# max32630 register map
Vendor: Maxim Integrated; Series: max3263x; File version: 1.2
CPU: CM4 r0p1, little endian, no MPU, FPU, 3 interrupt priority bits
Registers are 32-bit, read-write, reset 0x0 unless marked. A register's access mark holds for its fields unless they carry their own. Offsets are from the block's base; [hi:lo] are bit positions; 'fields as' and 'values as' point back to an identical list.

## GPIO — General Purpose I/O Ports (GPIO)
Base 0x4000A000
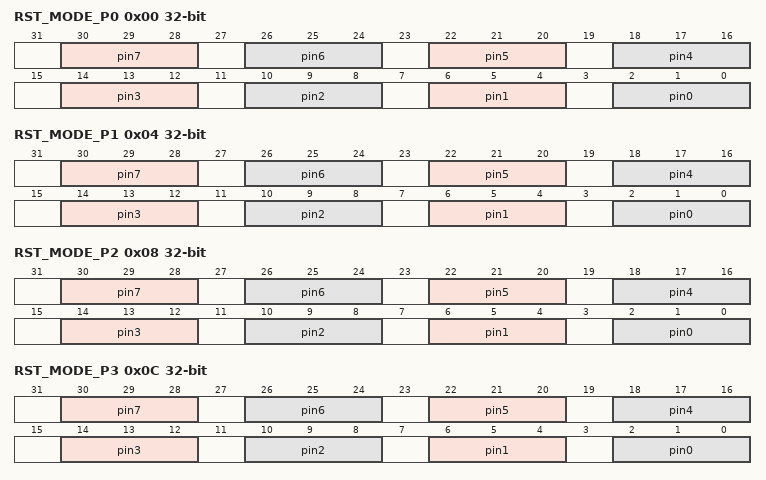
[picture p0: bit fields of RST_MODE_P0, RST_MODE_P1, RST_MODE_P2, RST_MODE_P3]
0x00 RST_MODE_P0 — Port P0 Default (Power-On Reset) Output Drive Mode
  [30:28] pin7 — P0.7 Default Output Drive Mode
  [26:24] pin6 — P0.6 Default Output Drive Mode
  [22:20] pin5 — P0.5 Default Output Drive Mode
  [18:16] pin4 — P0.4 Default Output Drive Mode
  [14:12] pin3 — P0.3 Default Output Drive Mode
  [10:8] pin2 — P0.2 Default Output Drive Mode
  [6:4] pin1 — P0.1 Default Output Drive Mode
  [2:0] pin0 — P0.0 Default Output Drive Mode
0x04 RST_MODE_P1 — Port P1 Default (Power-On Reset) Output Drive Mode
  [30:28] pin7 — P1.7 Default Output Drive Mode
  [26:24] pin6 — P1.6 Default Output Drive Mode
  [22:20] pin5 — P1.5 Default Output Drive Mode
  [18:16] pin4 — P1.4 Default Output Drive Mode
  [14:12] pin3 — P1.3 Default Output Drive Mode
  [10:8] pin2 — P1.2 Default Output Drive Mode
  [6:4] pin1 — P1.1 Default Output Drive Mode
  [2:0] pin0 — P1.0 Default Output Drive Mode
0x08 RST_MODE_P2 — Port P2 Default (Power-On Reset) Output Drive Mode
  [30:28] pin7 — P2.7 Default Output Drive Mode
  [26:24] pin6 — P2.6 Default Output Drive Mode
  [22:20] pin5 — P2.5 Default Output Drive Mode
  [18:16] pin4 — P2.4 Default Output Drive Mode
  [14:12] pin3 — P2.3 Default Output Drive Mode
  [10:8] pin2 — P2.2 Default Output Drive Mode
  [6:4] pin1 — P2.1 Default Output Drive Mode
  [2:0] pin0 — P2.0 Default Output Drive Mode
0x0C RST_MODE_P3 — Port P3 Default (Power-On Reset) Output Drive Mode
  [30:28] pin7 — P3.7 Default Output Drive Mode
  [26:24] pin6 — P3.6 Default Output Drive Mode
  [22:20] pin5 — P3.5 Default Output Drive Mode
  [18:16] pin4 — P3.4 Default Output Drive Mode
  [14:12] pin3 — P3.3 Default Output Drive Mode
  [10:8] pin2 — P3.2 Default Output Drive Mode
  [6:4] pin1 — P3.1 Default Output Drive Mode
  [2:0] pin0 — P3.0 Default Output Drive Mode
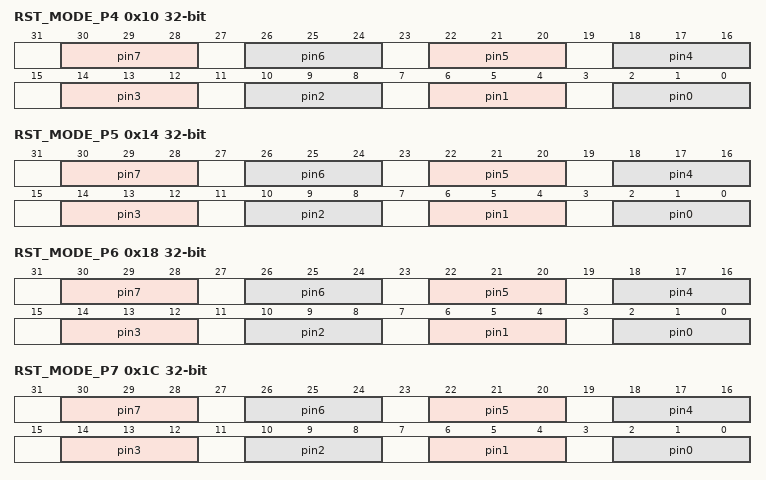
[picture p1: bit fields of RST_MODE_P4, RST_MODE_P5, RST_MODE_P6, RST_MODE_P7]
0x10 RST_MODE_P4 — Port P4 Default (Power-On Reset) Output Drive Mode
  [30:28] pin7 — P4.7 Default Output Drive Mode
  [26:24] pin6 — P4.6 Default Output Drive Mode
  [22:20] pin5 — P4.5 Default Output Drive Mode
  [18:16] pin4 — P4.4 Default Output Drive Mode
  [14:12] pin3 — P4.3 Default Output Drive Mode
  [10:8] pin2 — P4.2 Default Output Drive Mode
  [6:4] pin1 — P4.1 Default Output Drive Mode
  [2:0] pin0 — P4.0 Default Output Drive Mode
0x14 RST_MODE_P5 — Port P5 Default (Power-On Reset) Output Drive Mode
  [30:28] pin7 — P5.7 Default Output Drive Mode
  [26:24] pin6 — P5.6 Default Output Drive Mode
  [22:20] pin5 — P5.5 Default Output Drive Mode
  [18:16] pin4 — P5.4 Default Output Drive Mode
  [14:12] pin3 — P5.3 Default Output Drive Mode
  [10:8] pin2 — P5.2 Default Output Drive Mode
  [6:4] pin1 — P5.1 Default Output Drive Mode
  [2:0] pin0 — P5.0 Default Output Drive Mode
0x18 RST_MODE_P6 — Port P6 Default (Power-On Reset) Output Drive Mode
  [30:28] pin7 — P6.7 Default Output Drive Mode
  [26:24] pin6 — P6.6 Default Output Drive Mode
  [22:20] pin5 — P6.5 Default Output Drive Mode
  [18:16] pin4 — P6.4 Default Output Drive Mode
  [14:12] pin3 — P6.3 Default Output Drive Mode
  [10:8] pin2 — P6.2 Default Output Drive Mode
  [6:4] pin1 — P6.1 Default Output Drive Mode
  [2:0] pin0 — P6.0 Default Output Drive Mode
0x1C RST_MODE_P7 — Port P7 Default (Power-On Reset) Output Drive Mode
  [30:28] pin7 — P7.7 Default Output Drive Mode
  [26:24] pin6 — P7.6 Default Output Drive Mode
  [22:20] pin5 — P7.5 Default Output Drive Mode
  [18:16] pin4 — P7.4 Default Output Drive Mode
  [14:12] pin3 — P7.3 Default Output Drive Mode
  [10:8] pin2 — P7.2 Default Output Drive Mode
  [6:4] pin1 — P7.1 Default Output Drive Mode
  [2:0] pin0 — P7.0 Default Output Drive Mode
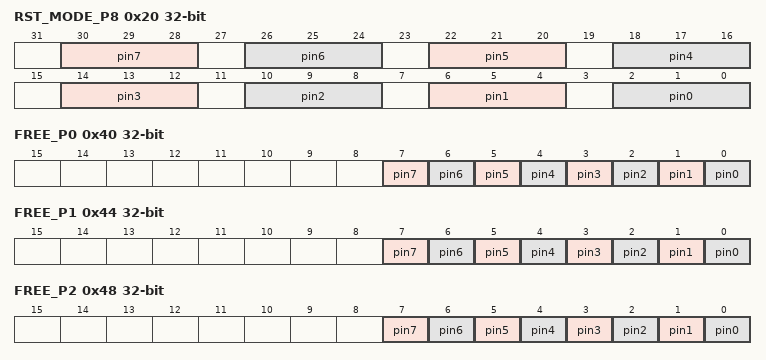
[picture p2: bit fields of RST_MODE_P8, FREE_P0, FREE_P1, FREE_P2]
0x20 RST_MODE_P8 — Port P8 Default (Power-On Reset) Output Drive Mode
  [30:28] pin7 — P8.7 Default Output Drive Mode
  [26:24] pin6 — P8.6 Default Output Drive Mode
  [22:20] pin5 — P8.5 Default Output Drive Mode
  [18:16] pin4 — P8.4 Default Output Drive Mode
  [14:12] pin3 — P8.3 Default Output Drive Mode
  [10:8] pin2 — P8.2 Default Output Drive Mode
  [6:4] pin1 — P8.1 Default Output Drive Mode
  [2:0] pin0 — P8.0 Default Output Drive Mode
0x40 FREE_P0 — Port P0 Free for GPIO Operation Flags
  [7] pin7 ro — P0.7 GPIO Mode Acknowledge
  [6] pin6 ro — P0.6 GPIO Mode Acknowledge
  [5] pin5 ro — P0.5 GPIO Mode Acknowledge
  [4] pin4 ro — P0.4 GPIO Mode Acknowledge
  [3] pin3 ro — P0.3 GPIO Mode Acknowledge
  [2] pin2 ro — P0.2 GPIO Mode Acknowledge
  [1] pin1 ro — P0.1 GPIO Mode Acknowledge
  [0] pin0 ro — P0.0 GPIO Mode Acknowledge
0x44 FREE_P1 — Port P1 Free for GPIO Operation Flags
  [7] pin7 ro — P1.7 GPIO Mode Acknowledge
  [6] pin6 ro — P1.6 GPIO Mode Acknowledge
  [5] pin5 ro — P1.5 GPIO Mode Acknowledge
  [4] pin4 ro — P1.4 GPIO Mode Acknowledge
  [3] pin3 ro — P1.3 GPIO Mode Acknowledge
  [2] pin2 ro — P1.2 GPIO Mode Acknowledge
  [1] pin1 ro — P1.1 GPIO Mode Acknowledge
  [0] pin0 ro — P1.0 GPIO Mode Acknowledge
0x48 FREE_P2 — Port P2 Free for GPIO Operation Flags
  [7] pin7 ro — P2.7 GPIO Mode Acknowledge
  [6] pin6 ro — P2.6 GPIO Mode Acknowledge
  [5] pin5 ro — P2.5 GPIO Mode Acknowledge
  [4] pin4 ro — P2.4 GPIO Mode Acknowledge
  [3] pin3 ro — P2.3 GPIO Mode Acknowledge
  [2] pin2 ro — P2.2 GPIO Mode Acknowledge
  [1] pin1 ro — P2.1 GPIO Mode Acknowledge
  [0] pin0 ro — P2.0 GPIO Mode Acknowledge
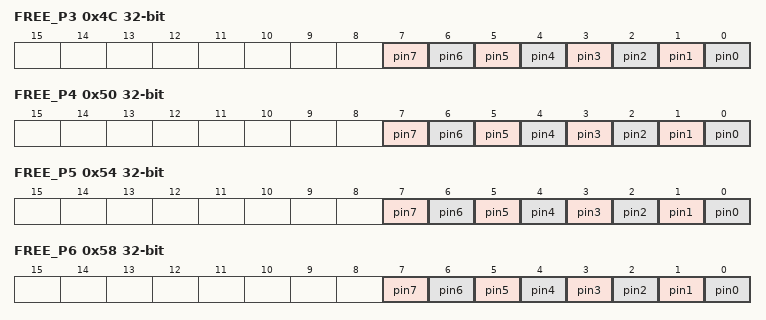
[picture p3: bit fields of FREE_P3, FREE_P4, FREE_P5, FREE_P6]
0x4C FREE_P3 — Port P3 Free for GPIO Operation Flags
  [7] pin7 ro — P3.7 GPIO Mode Acknowledge
  [6] pin6 ro — P3.6 GPIO Mode Acknowledge
  [5] pin5 ro — P3.5 GPIO Mode Acknowledge
  [4] pin4 ro — P3.4 GPIO Mode Acknowledge
  [3] pin3 ro — P3.3 GPIO Mode Acknowledge
  [2] pin2 ro — P3.2 GPIO Mode Acknowledge
  [1] pin1 ro — P3.1 GPIO Mode Acknowledge
  [0] pin0 ro — P3.0 GPIO Mode Acknowledge
0x50 FREE_P4 — Port P4 Free for GPIO Operation Flags
  [7] pin7 ro — P4.7 GPIO Mode Acknowledge
  [6] pin6 ro — P4.6 GPIO Mode Acknowledge
  [5] pin5 ro — P4.5 GPIO Mode Acknowledge
  [4] pin4 ro — P4.4 GPIO Mode Acknowledge
  [3] pin3 ro — P4.3 GPIO Mode Acknowledge
  [2] pin2 ro — P4.2 GPIO Mode Acknowledge
  [1] pin1 ro — P4.1 GPIO Mode Acknowledge
  [0] pin0 ro — P4.0 GPIO Mode Acknowledge
0x54 FREE_P5 — Port P5 Free for GPIO Operation Flags
  [7] pin7 ro — P5.7 GPIO Mode Acknowledge
  [6] pin6 ro — P5.6 GPIO Mode Acknowledge
  [5] pin5 ro — P5.5 GPIO Mode Acknowledge
  [4] pin4 ro — P5.4 GPIO Mode Acknowledge
  [3] pin3 ro — P5.3 GPIO Mode Acknowledge
  [2] pin2 ro — P5.2 GPIO Mode Acknowledge
  [1] pin1 ro — P5.1 GPIO Mode Acknowledge
  [0] pin0 ro — P5.0 GPIO Mode Acknowledge
0x58 FREE_P6 — Port P6 Free for GPIO Operation Flags
  [7] pin7 ro — P6.7 GPIO Mode Acknowledge
  [6] pin6 ro — P6.6 GPIO Mode Acknowledge
  [5] pin5 ro — P6.5 GPIO Mode Acknowledge
  [4] pin4 ro — P6.4 GPIO Mode Acknowledge
  [3] pin3 ro — P6.3 GPIO Mode Acknowledge
  [2] pin2 ro — P6.2 GPIO Mode Acknowledge
  [1] pin1 ro — P6.1 GPIO Mode Acknowledge
  [0] pin0 ro — P6.0 GPIO Mode Acknowledge
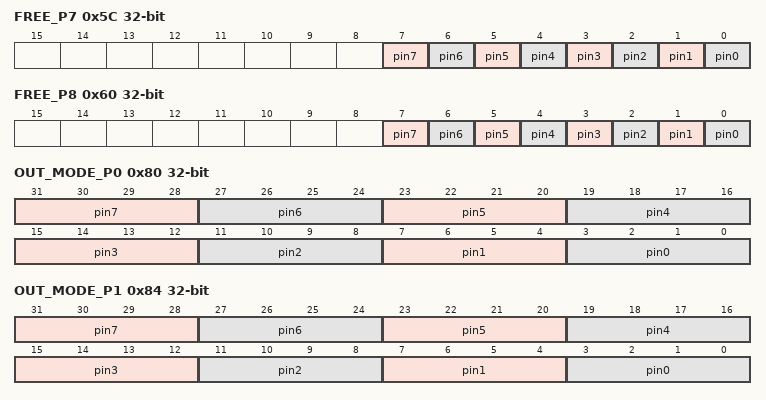
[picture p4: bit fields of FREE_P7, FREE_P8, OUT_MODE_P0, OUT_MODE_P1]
0x5C FREE_P7 — Port P7 Free for GPIO Operation Flags
  [7] pin7 ro — P7.7 GPIO Mode Acknowledge
  [6] pin6 ro — P7.6 GPIO Mode Acknowledge
  [5] pin5 ro — P7.5 GPIO Mode Acknowledge
  [4] pin4 ro — P7.4 GPIO Mode Acknowledge
  [3] pin3 ro — P7.3 GPIO Mode Acknowledge
  [2] pin2 ro — P7.2 GPIO Mode Acknowledge
  [1] pin1 ro — P7.1 GPIO Mode Acknowledge
  [0] pin0 ro — P7.0 GPIO Mode Acknowledge
0x60 FREE_P8 — Port P8 Free for GPIO Operation Flags
  [7] pin7 ro — P8.7 (Not Implemented)
  [6] pin6 ro — P8.6 (Not Implemented)
  [5] pin5 ro — P8.5 (Not Implemented)
  [4] pin4 ro — P8.4 (Not Implemented)
  [3] pin3 ro — P8.3 (Not Implemented)
  [2] pin2 ro — P8.2 (Not Implemented)
  [1] pin1 ro — P8.1 GPIO Mode Acknowledge
  [0] pin0 ro — P8.0 GPIO Mode Acknowledge
0x80 OUT_MODE_P0 — Port P0 GPIO Output Drive Mode
  [31:28] pin7 — P0.7 Output Drive Mode
  [27:24] pin6 — P0.6 Output Drive Mode
  [23:20] pin5 — P0.5 Output Drive Mode
  [19:16] pin4 — P0.4 Output Drive Mode
  [15:12] pin3 — P0.3 Output Drive Mode
  [11:8] pin2 — P0.2 Output Drive Mode
  [7:4] pin1 — P0.1 Output Drive Mode
  [3:0] pin0 — P0.0 Output Drive Mode
0x84 OUT_MODE_P1 — Port P1 GPIO Output Drive Mode
  [31:28] pin7 — P1.7 Output Drive Mode
  [27:24] pin6 — P1.6 Output Drive Mode
  [23:20] pin5 — P1.5 Output Drive Mode
  [19:16] pin4 — P1.4 Output Drive Mode
  [15:12] pin3 — P1.3 Output Drive Mode
  [11:8] pin2 — P1.2 Output Drive Mode
  [7:4] pin1 — P1.1 Output Drive Mode
  [3:0] pin0 — P1.0 Output Drive Mode
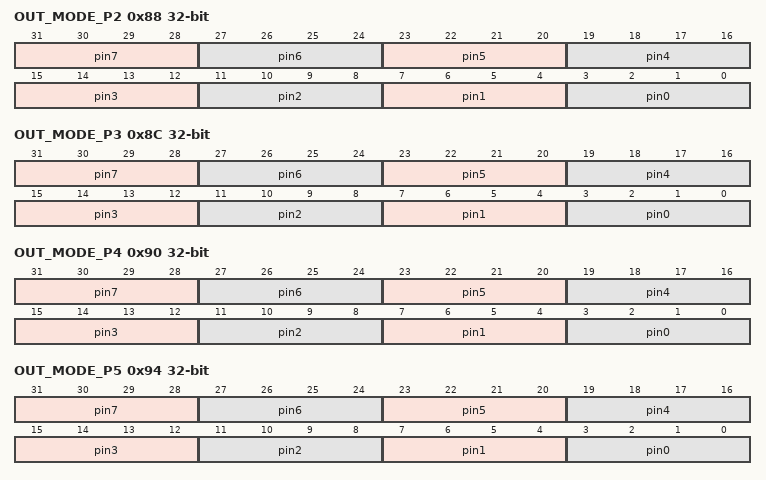
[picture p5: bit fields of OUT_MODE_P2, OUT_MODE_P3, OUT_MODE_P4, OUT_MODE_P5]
0x88 OUT_MODE_P2 — Port P2 GPIO Output Drive Mode
  [31:28] pin7 — P2.7 Output Drive Mode
  [27:24] pin6 — P2.6 Output Drive Mode
  [23:20] pin5 — P2.5 Output Drive Mode
  [19:16] pin4 — P2.4 Output Drive Mode
  [15:12] pin3 — P2.3 Output Drive Mode
  [11:8] pin2 — P2.2 Output Drive Mode
  [7:4] pin1 — P2.1 Output Drive Mode
  [3:0] pin0 — P2.0 Output Drive Mode
0x8C OUT_MODE_P3 — Port P3 GPIO Output Drive Mode
  [31:28] pin7 — P3.7 Output Drive Mode
  [27:24] pin6 — P3.6 Output Drive Mode
  [23:20] pin5 — P3.5 Output Drive Mode
  [19:16] pin4 — P3.4 Output Drive Mode
  [15:12] pin3 — P3.3 Output Drive Mode
  [11:8] pin2 — P3.2 Output Drive Mode
  [7:4] pin1 — P3.1 Output Drive Mode
  [3:0] pin0 — P3.0 Output Drive Mode
0x90 OUT_MODE_P4 — Port P4 GPIO Output Drive Mode
  [31:28] pin7 — P4.7 Output Drive Mode
  [27:24] pin6 — P4.6 Output Drive Mode
  [23:20] pin5 — P4.5 Output Drive Mode
  [19:16] pin4 — P4.4 Output Drive Mode
  [15:12] pin3 — P4.3 Output Drive Mode
  [11:8] pin2 — P4.2 Output Drive Mode
  [7:4] pin1 — P4.1 Output Drive Mode
  [3:0] pin0 — P4.0 Output Drive Mode
0x94 OUT_MODE_P5 — Port P5 GPIO Output Drive Mode
  [31:28] pin7 — P5.7 Output Drive Mode
  [27:24] pin6 — P5.6 Output Drive Mode
  [23:20] pin5 — P5.5 Output Drive Mode
  [19:16] pin4 — P5.4 Output Drive Mode
  [15:12] pin3 — P5.3 Output Drive Mode
  [11:8] pin2 — P5.2 Output Drive Mode
  [7:4] pin1 — P5.1 Output Drive Mode
  [3:0] pin0 — P5.0 Output Drive Mode
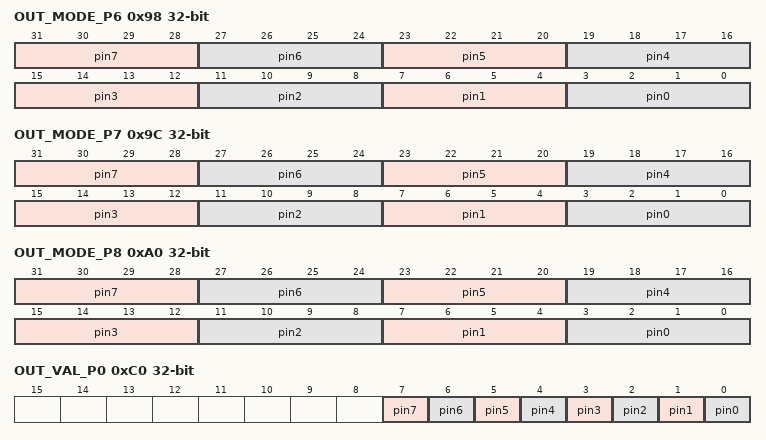
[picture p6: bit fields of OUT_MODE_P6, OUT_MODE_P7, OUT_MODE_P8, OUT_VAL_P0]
0x98 OUT_MODE_P6 — Port P6 GPIO Output Drive Mode
  [31:28] pin7 — P6.7 Output Drive Mode
  [27:24] pin6 — P6.6 Output Drive Mode
  [23:20] pin5 — P6.5 Output Drive Mode
  [19:16] pin4 — P6.4 Output Drive Mode
  [15:12] pin3 — P6.3 Output Drive Mode
  [11:8] pin2 — P6.2 Output Drive Mode
  [7:4] pin1 — P6.1 Output Drive Mode
  [3:0] pin0 — P6.0 Output Drive Mode
0x9C OUT_MODE_P7 — Port P7 GPIO Output Drive Mode
  [31:28] pin7 — P7.7 Output Drive Mode
  [27:24] pin6 — P7.6 Output Drive Mode
  [23:20] pin5 — P7.5 Output Drive Mode
  [19:16] pin4 — P7.4 Output Drive Mode
  [15:12] pin3 — P7.3 Output Drive Mode
  [11:8] pin2 — P7.2 Output Drive Mode
  [7:4] pin1 — P7.1 Output Drive Mode
  [3:0] pin0 — P7.0 Output Drive Mode
0xA0 OUT_MODE_P8 — Port P8 GPIO Output Drive Mode
  [31:28] pin7 — P8.7 (No Connect)
  [27:24] pin6 — P8.6 (No Connect)
  [23:20] pin5 — P8.5 (No Connect)
  [19:16] pin4 — P8.4 (No Connect)
  [15:12] pin3 — P8.3 (No Connect)
  [11:8] pin2 — P8.2 (No Connect)
  [7:4] pin1 — P8.1 Output Drive Mode
  [3:0] pin0 — P8.0 Output Drive Mode
0xC0 OUT_VAL_P0 — Port P0 GPIO Output Value
  [7] pin7 — P0.7 GPIO Output Drive Value
  [6] pin6 — P0.6 GPIO Output Drive Value
  [5] pin5 — P0.5 GPIO Output Drive Value
  [4] pin4 — P0.4 GPIO Output Drive Value
  [3] pin3 — P0.3 GPIO Output Drive Value
  [2] pin2 — P0.2 GPIO Output Drive Value
  [1] pin1 — P0.1 GPIO Output Drive Value
  [0] pin0 — P0.0 GPIO Output Drive Value
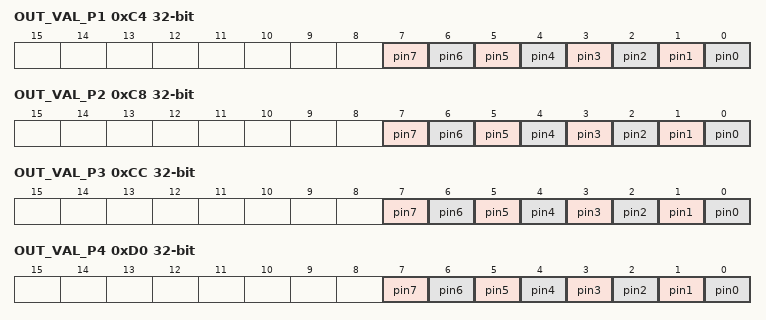
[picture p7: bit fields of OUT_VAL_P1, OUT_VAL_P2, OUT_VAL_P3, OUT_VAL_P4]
0xC4 OUT_VAL_P1 — Port P1 GPIO Output Value
  [7] pin7 — P1.7 GPIO Output Drive Value
  [6] pin6 — P1.6 GPIO Output Drive Value
  [5] pin5 — P1.5 GPIO Output Drive Value
  [4] pin4 — P1.4 GPIO Output Drive Value
  [3] pin3 — P1.3 GPIO Output Drive Value
  [2] pin2 — P1.2 GPIO Output Drive Value
  [1] pin1 — P1.1 GPIO Output Drive Value
  [0] pin0 — P1.0 GPIO Output Drive Value
0xC8 OUT_VAL_P2 — Port P2 GPIO Output Value
  [7] pin7 — P2.7 GPIO Output Drive Value
  [6] pin6 — P2.6 GPIO Output Drive Value
  [5] pin5 — P2.5 GPIO Output Drive Value
  [4] pin4 — P2.4 GPIO Output Drive Value
  [3] pin3 — P2.3 GPIO Output Drive Value
  [2] pin2 — P2.2 GPIO Output Drive Value
  [1] pin1 — P2.1 GPIO Output Drive Value
  [0] pin0 — P2.0 GPIO Output Drive Value
0xCC OUT_VAL_P3 — Port P3 GPIO Output Value
  [7] pin7 — P3.7 GPIO Output Drive Value
  [6] pin6 — P3.6 GPIO Output Drive Value
  [5] pin5 — P3.5 GPIO Output Drive Value
  [4] pin4 — P3.4 GPIO Output Drive Value
  [3] pin3 — P3.3 GPIO Output Drive Value
  [2] pin2 — P3.2 GPIO Output Drive Value
  [1] pin1 — P3.1 GPIO Output Drive Value
  [0] pin0 — P3.0 GPIO Output Drive Value
0xD0 OUT_VAL_P4 — Port P4 GPIO Output Value
  [7] pin7 — P4.7 GPIO Output Drive Value
  [6] pin6 — P4.6 GPIO Output Drive Value
  [5] pin5 — P4.5 GPIO Output Drive Value
  [4] pin4 — P4.4 GPIO Output Drive Value
  [3] pin3 — P4.3 GPIO Output Drive Value
  [2] pin2 — P4.2 GPIO Output Drive Value
  [1] pin1 — P4.1 GPIO Output Drive Value
  [0] pin0 — P4.0 GPIO Output Drive Value
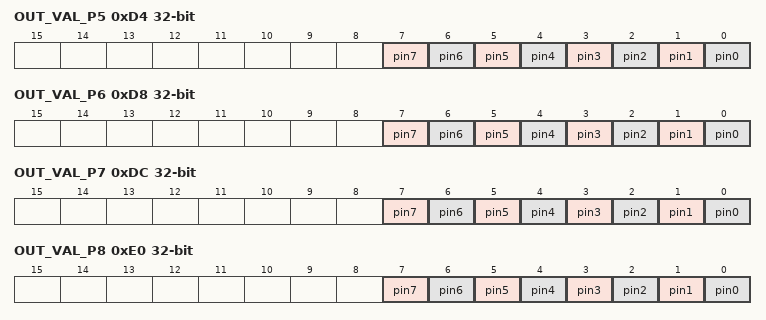
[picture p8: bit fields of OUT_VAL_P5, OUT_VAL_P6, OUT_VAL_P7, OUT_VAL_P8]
0xD4 OUT_VAL_P5 — Port P5 GPIO Output Value
  [7] pin7 — P5.7 GPIO Output Drive Value
  [6] pin6 — P5.6 GPIO Output Drive Value
  [5] pin5 — P5.5 GPIO Output Drive Value
  [4] pin4 — P5.4 GPIO Output Drive Value
  [3] pin3 — P5.3 GPIO Output Drive Value
  [2] pin2 — P5.2 GPIO Output Drive Value
  [1] pin1 — P5.1 GPIO Output Drive Value
  [0] pin0 — P5.0 GPIO Output Drive Value
0xD8 OUT_VAL_P6 — Port P6 GPIO Output Value
  [7] pin7 — P6.7 GPIO Output Drive Value
  [6] pin6 — P6.6 GPIO Output Drive Value
  [5] pin5 — P6.5 GPIO Output Drive Value
  [4] pin4 — P6.4 GPIO Output Drive Value
  [3] pin3 — P6.3 GPIO Output Drive Value
  [2] pin2 — P6.2 GPIO Output Drive Value
  [1] pin1 — P6.1 GPIO Output Drive Value
  [0] pin0 — P6.0 GPIO Output Drive Value
0xDC OUT_VAL_P7 — Port P7 GPIO Output Value
  [7] pin7 — P7.7 GPIO Output Drive Value
  [6] pin6 — P7.6 GPIO Output Drive Value
  [5] pin5 — P7.5 GPIO Output Drive Value
  [4] pin4 — P7.4 GPIO Output Drive Value
  [3] pin3 — P7.3 GPIO Output Drive Value
  [2] pin2 — P7.2 GPIO Output Drive Value
  [1] pin1 — P7.1 GPIO Output Drive Value
  [0] pin0 — P7.0 GPIO Output Drive Value
0xE0 OUT_VAL_P8 — Port P8 GPIO Output Value
  [7] pin7 — P8.7 (No Connect)
  [6] pin6 — P8.6 (No Connect)
  [5] pin5 — P8.5 (No Connect)
  [4] pin4 — P8.4 (No Connect)
  [3] pin3 — P8.3 (No Connect)
  [2] pin2 — P8.2 (No Connect)
  [1] pin1 — P8.1 GPIO Output Drive Value
  [0] pin0 — P8.0 GPIO Output Drive Value
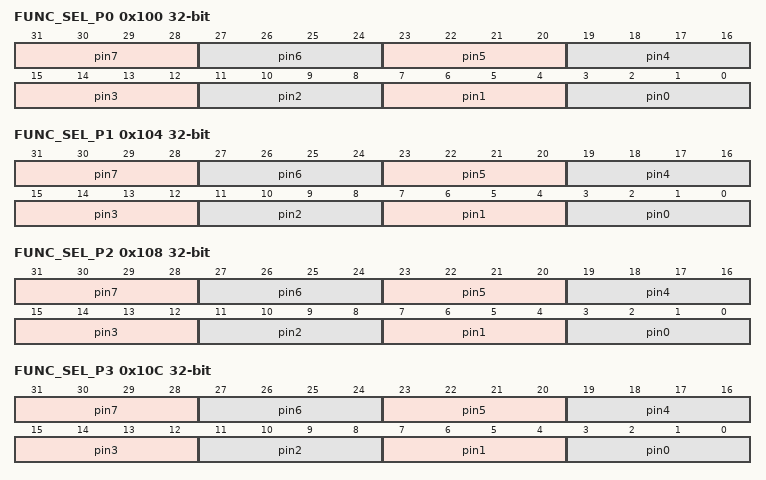
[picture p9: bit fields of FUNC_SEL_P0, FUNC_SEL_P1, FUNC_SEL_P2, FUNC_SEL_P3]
0x100 FUNC_SEL_P0 — Port P0 GPIO Function Select
  [all] fields
    0=MODE_GPIO (GPIO pin I/O is controlled by output mode and output value fields.); 1=MODE_PT (GPIO pin output is controlled by a pulse train output.); 2=MODE_TMR (GPIO pin is a 32-bit timer input or output (depending on timer configuration).)
  [31:28] pin7 — P0.7 Output Function Select
  [27:24] pin6 — P0.6 Output Function Select
  [23:20] pin5 — P0.5 Output Function Select
  [19:16] pin4 — P0.4 Output Function Select
  [15:12] pin3 — P0.3 Output Function Select
  [11:8] pin2 — P0.2 Output Function Select
  [7:4] pin1 — P0.1 Output Function Select
  [3:0] pin0 — P0.0 Output Function Select
0x104 FUNC_SEL_P1 — Port P1 GPIO Function Select
  [all] fields
    values as the fields of FUNC_SEL_P0
  [31:28] pin7 — P1.7 Output Function Select
  [27:24] pin6 — P1.6 Output Function Select
  [23:20] pin5 — P1.5 Output Function Select
  [19:16] pin4 — P1.4 Output Function Select
  [15:12] pin3 — P1.3 Output Function Select
  [11:8] pin2 — P1.2 Output Function Select
  [7:4] pin1 — P1.1 Output Function Select
  [3:0] pin0 — P1.0 Output Function Select
0x108 FUNC_SEL_P2 — Port P2 GPIO Function Select
  [all] fields
    values as the fields of FUNC_SEL_P0
  [31:28] pin7 — P2.7 Output Function Select
  [27:24] pin6 — P2.6 Output Function Select
  [23:20] pin5 — P2.5 Output Function Select
  [19:16] pin4 — P2.4 Output Function Select
  [15:12] pin3 — P2.3 Output Function Select
  [11:8] pin2 — P2.2 Output Function Select
  [7:4] pin1 — P2.1 Output Function Select
  [3:0] pin0 — P2.0 Output Function Select
0x10C FUNC_SEL_P3 — Port P3 GPIO Function Select
  [all] fields
    values as the fields of FUNC_SEL_P0
  [31:28] pin7 — P3.7 Output Function Select
  [27:24] pin6 — P3.6 Output Function Select
  [23:20] pin5 — P3.5 Output Function Select
  [19:16] pin4 — P3.4 Output Function Select
  [15:12] pin3 — P3.3 Output Function Select
  [11:8] pin2 — P3.2 Output Function Select
  [7:4] pin1 — P3.1 Output Function Select
  [3:0] pin0 — P3.0 Output Function Select
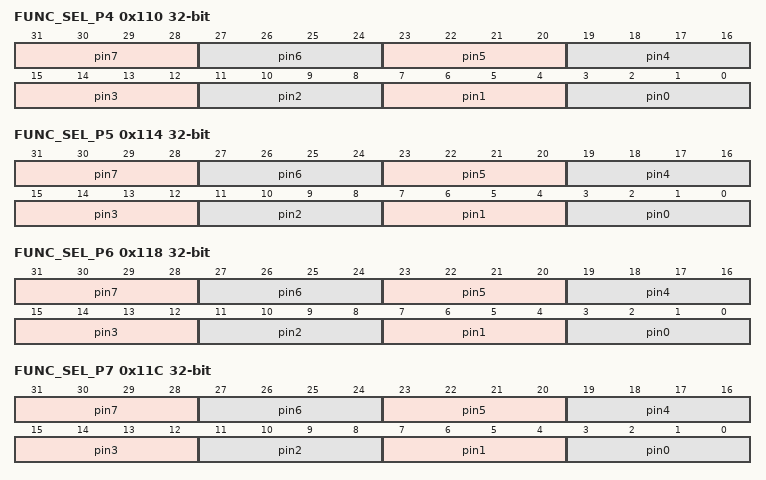
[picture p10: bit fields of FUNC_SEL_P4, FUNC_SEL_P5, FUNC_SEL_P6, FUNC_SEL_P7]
0x110 FUNC_SEL_P4 — Port P4 GPIO Function Select
  [all] fields
    values as the fields of FUNC_SEL_P0
  [31:28] pin7 — P4.7 Output Function Select
  [27:24] pin6 — P4.6 Output Function Select
  [23:20] pin5 — P4.5 Output Function Select
  [19:16] pin4 — P4.4 Output Function Select
  [15:12] pin3 — P4.3 Output Function Select
  [11:8] pin2 — P4.2 Output Function Select
  [7:4] pin1 — P4.1 Output Function Select
  [3:0] pin0 — P4.0 Output Function Select
0x114 FUNC_SEL_P5 — Port P5 GPIO Function Select
  [all] fields
    values as the fields of FUNC_SEL_P0
  [31:28] pin7 — P5.7 Output Function Select
  [27:24] pin6 — P5.6 Output Function Select
  [23:20] pin5 — P5.5 Output Function Select
  [19:16] pin4 — P5.4 Output Function Select
  [15:12] pin3 — P5.3 Output Function Select
  [11:8] pin2 — P5.2 Output Function Select
  [7:4] pin1 — P5.1 Output Function Select
  [3:0] pin0 — P5.0 Output Function Select
0x118 FUNC_SEL_P6 — Port P6 GPIO Function Select
  [all] fields
    values as the fields of FUNC_SEL_P0
  [31:28] pin7 — P6.7 Output Function Select
  [27:24] pin6 — P6.6 Output Function Select
  [23:20] pin5 — P6.5 Output Function Select
  [19:16] pin4 — P6.4 Output Function Select
  [15:12] pin3 — P6.3 Output Function Select
  [11:8] pin2 — P6.2 Output Function Select
  [7:4] pin1 — P6.1 Output Function Select
  [3:0] pin0 — P6.0 Output Function Select
0x11C FUNC_SEL_P7 — Port P7 GPIO Function Select
  [all] fields
    values as the fields of FUNC_SEL_P0
  [31:28] pin7 — P7.7 Output Function Select
  [27:24] pin6 — P7.6 Output Function Select
  [23:20] pin5 — P7.5 Output Function Select
  [19:16] pin4 — P7.4 Output Function Select
  [15:12] pin3 — P7.3 Output Function Select
  [11:8] pin2 — P7.2 Output Function Select
  [7:4] pin1 — P7.1 Output Function Select
  [3:0] pin0 — P7.0 Output Function Select
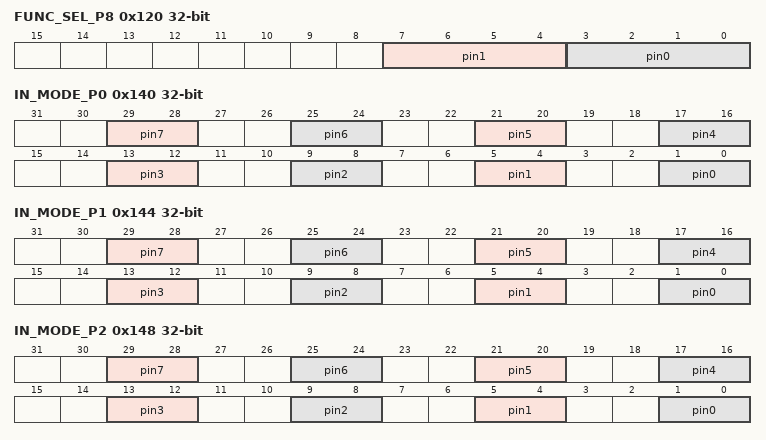
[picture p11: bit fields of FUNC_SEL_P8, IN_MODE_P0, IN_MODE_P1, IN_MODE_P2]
0x120 FUNC_SEL_P8 — Port P8 GPIO Function Select
  [7:4] pin1 — P8.1 Output Function Select
    values as the fields of FUNC_SEL_P0
  [3:0] pin0 — P8.0 Output Function Select
    values as the fields of FUNC_SEL_P0
0x140 IN_MODE_P0 — Port P0 GPIO Input Monitoring Mode
  [29:28] pin7 — P0.7 Input Monitoring Mode
  [25:24] pin6 — P0.6 Input Monitoring Mode
  [21:20] pin5 — P0.5 Input Monitoring Mode
  [17:16] pin4 — P0.4 Input Monitoring Mode
  [13:12] pin3 — P0.3 Input Monitoring Mode
  [9:8] pin2 — P0.2 Input Monitoring Mode
  [5:4] pin1 — P0.1 Input Monitoring Mode
  [1:0] pin0 — P0.0 Input Monitoring Mode
0x144 IN_MODE_P1 — Port P1 GPIO Input Monitoring Mode
  [29:28] pin7 — P1.7 Input Monitoring Mode
  [25:24] pin6 — P1.6 Input Monitoring Mode
  [21:20] pin5 — P1.5 Input Monitoring Mode
  [17:16] pin4 — P1.4 Input Monitoring Mode
  [13:12] pin3 — P1.3 Input Monitoring Mode
  [9:8] pin2 — P1.2 Input Monitoring Mode
  [5:4] pin1 — P1.1 Input Monitoring Mode
  [1:0] pin0 — P1.0 Input Monitoring Mode
0x148 IN_MODE_P2 — Port P2 GPIO Input Monitoring Mode
  [29:28] pin7 — P2.7 Input Monitoring Mode
  [25:24] pin6 — P2.6 Input Monitoring Mode
  [21:20] pin5 — P2.5 Input Monitoring Mode
  [17:16] pin4 — P2.4 Input Monitoring Mode
  [13:12] pin3 — P2.3 Input Monitoring Mode
  [9:8] pin2 — P2.2 Input Monitoring Mode
  [5:4] pin1 — P2.1 Input Monitoring Mode
  [1:0] pin0 — P2.0 Input Monitoring Mode
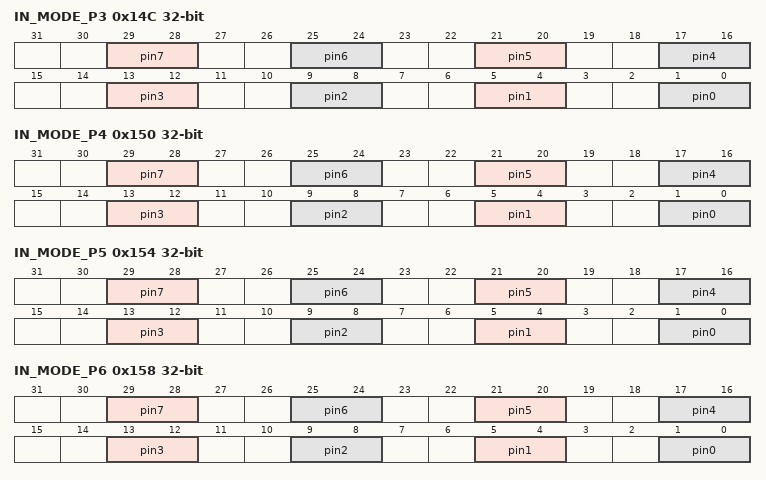
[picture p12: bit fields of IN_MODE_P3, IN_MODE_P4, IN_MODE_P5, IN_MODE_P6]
0x14C IN_MODE_P3 — Port P3 GPIO Input Monitoring Mode
  [29:28] pin7 — P3.7 Input Monitoring Mode
  [25:24] pin6 — P3.6 Input Monitoring Mode
  [21:20] pin5 — P3.5 Input Monitoring Mode
  [17:16] pin4 — P3.4 Input Monitoring Mode
  [13:12] pin3 — P3.3 Input Monitoring Mode
  [9:8] pin2 — P3.2 Input Monitoring Mode
  [5:4] pin1 — P3.1 Input Monitoring Mode
  [1:0] pin0 — P3.0 Input Monitoring Mode
0x150 IN_MODE_P4 — Port P4 GPIO Input Monitoring Mode
  [29:28] pin7 — P4.7 Input Monitoring Mode
  [25:24] pin6 — P4.6 Input Monitoring Mode
  [21:20] pin5 — P4.5 Input Monitoring Mode
  [17:16] pin4 — P4.4 Input Monitoring Mode
  [13:12] pin3 — P4.3 Input Monitoring Mode
  [9:8] pin2 — P4.2 Input Monitoring Mode
  [5:4] pin1 — P4.1 Input Monitoring Mode
  [1:0] pin0 — P4.0 Input Monitoring Mode
0x154 IN_MODE_P5 — Port P5 GPIO Input Monitoring Mode
  [29:28] pin7 — P5.7 Input Monitoring Mode
  [25:24] pin6 — P5.6 Input Monitoring Mode
  [21:20] pin5 — P5.5 Input Monitoring Mode
  [17:16] pin4 — P5.4 Input Monitoring Mode
  [13:12] pin3 — P5.3 Input Monitoring Mode
  [9:8] pin2 — P5.2 Input Monitoring Mode
  [5:4] pin1 — P5.1 Input Monitoring Mode
  [1:0] pin0 — P5.0 Input Monitoring Mode
0x158 IN_MODE_P6 — Port P6 GPIO Input Monitoring Mode
  [29:28] pin7 — P6.7 Input Monitoring Mode
  [25:24] pin6 — P6.6 Input Monitoring Mode
  [21:20] pin5 — P6.5 Input Monitoring Mode
  [17:16] pin4 — P6.4 Input Monitoring Mode
  [13:12] pin3 — P6.3 Input Monitoring Mode
  [9:8] pin2 — P6.2 Input Monitoring Mode
  [5:4] pin1 — P6.1 Input Monitoring Mode
  [1:0] pin0 — P6.0 Input Monitoring Mode
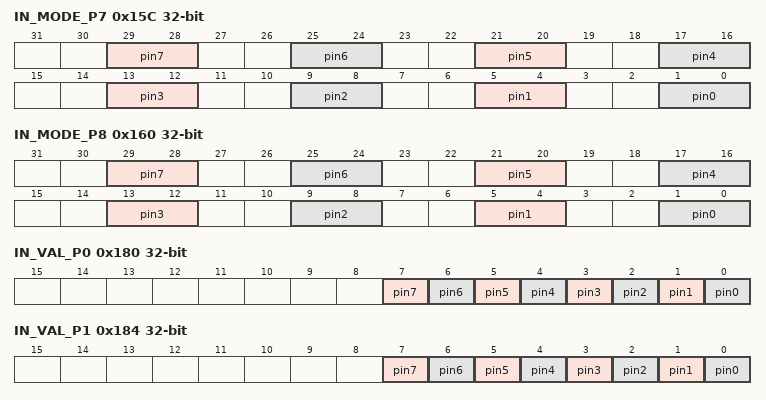
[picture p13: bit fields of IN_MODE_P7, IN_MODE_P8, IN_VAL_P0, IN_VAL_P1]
0x15C IN_MODE_P7 — Port P7 GPIO Input Monitoring Mode
  [29:28] pin7 — P7.7 Input Monitoring Mode
  [25:24] pin6 — P7.6 Input Monitoring Mode
  [21:20] pin5 — P7.5 Input Monitoring Mode
  [17:16] pin4 — P7.4 Input Monitoring Mode
  [13:12] pin3 — P7.3 Input Monitoring Mode
  [9:8] pin2 — P7.2 Input Monitoring Mode
  [5:4] pin1 — P7.1 Input Monitoring Mode
  [1:0] pin0 — P7.0 Input Monitoring Mode
0x160 IN_MODE_P8 — Port P8 GPIO Input Monitoring Mode
  [29:28] pin7 — P8.7 Input Monitoring Mode
  [25:24] pin6 — P8.6 Input Monitoring Mode
  [21:20] pin5 — P8.5 Input Monitoring Mode
  [17:16] pin4 — P8.4 Input Monitoring Mode
  [13:12] pin3 — P8.3 Input Monitoring Mode
  [9:8] pin2 — P8.2 Input Monitoring Mode
  [5:4] pin1 — P8.1 Input Monitoring Mode
  [1:0] pin0 — P8.0 Input Monitoring Mode
0x180 IN_VAL_P0 — Port P0 GPIO Input Value
  [7] pin7 ro — P0.7 Input Value
  [6] pin6 ro — P0.6 Input Value
  [5] pin5 ro — P0.5 Input Value
  [4] pin4 ro — P0.4 Input Value
  [3] pin3 ro — P0.3 Input Value
  [2] pin2 ro — P0.2 Input Value
  [1] pin1 ro — P0.1 Input Value
  [0] pin0 ro — P0.0 Input Value
0x184 IN_VAL_P1 — Port P1 GPIO Input Value
  [7] pin7 ro — P1.7 Input Value
  [6] pin6 ro — P1.6 Input Value
  [5] pin5 ro — P1.5 Input Value
  [4] pin4 ro — P1.4 Input Value
  [3] pin3 ro — P1.3 Input Value
  [2] pin2 ro — P1.2 Input Value
  [1] pin1 ro — P1.1 Input Value
  [0] pin0 ro — P1.0 Input Value
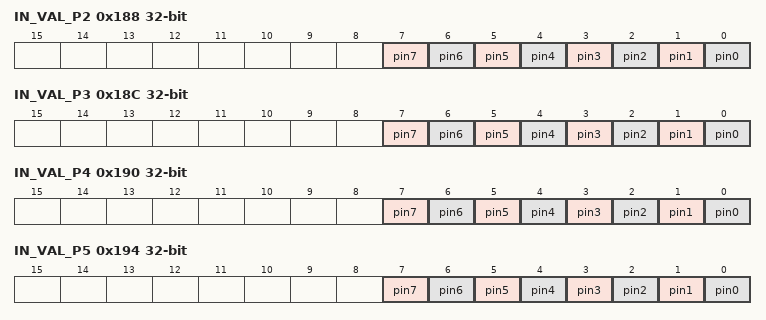
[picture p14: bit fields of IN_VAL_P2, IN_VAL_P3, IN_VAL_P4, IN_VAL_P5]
0x188 IN_VAL_P2 — Port P2 GPIO Input Value
  [7] pin7 ro — P2.7 Input Value
  [6] pin6 ro — P2.6 Input Value
  [5] pin5 ro — P2.5 Input Value
  [4] pin4 ro — P2.4 Input Value
  [3] pin3 ro — P2.3 Input Value
  [2] pin2 ro — P2.2 Input Value
  [1] pin1 ro — P2.1 Input Value
  [0] pin0 ro — P2.0 Input Value
0x18C IN_VAL_P3 — Port P3 GPIO Input Value
  [7] pin7 ro — P3.7 Input Value
  [6] pin6 ro — P3.6 Input Value
  [5] pin5 ro — P3.5 Input Value
  [4] pin4 ro — P3.4 Input Value
  [3] pin3 ro — P3.3 Input Value
  [2] pin2 ro — P3.2 Input Value
  [1] pin1 ro — P3.1 Input Value
  [0] pin0 ro — P3.0 Input Value
0x190 IN_VAL_P4 — Port P4 GPIO Input Value
  [7] pin7 ro — P4.7 Input Value
  [6] pin6 ro — P4.6 Input Value
  [5] pin5 ro — P4.5 Input Value
  [4] pin4 ro — P4.4 Input Value
  [3] pin3 ro — P4.3 Input Value
  [2] pin2 ro — P4.2 Input Value
  [1] pin1 ro — P4.1 Input Value
  [0] pin0 ro — P4.0 Input Value
0x194 IN_VAL_P5 — Port P5 GPIO Input Value
  [7] pin7 ro — P5.7 Input Value
  [6] pin6 ro — P5.6 Input Value
  [5] pin5 ro — P5.5 Input Value
  [4] pin4 ro — P5.4 Input Value
  [3] pin3 ro — P5.3 Input Value
  [2] pin2 ro — P5.2 Input Value
  [1] pin1 ro — P5.1 Input Value
  [0] pin0 ro — P5.0 Input Value
0x198 IN_VAL_P6 — Port P6 GPIO Input Value
  [7] pin7 ro — P6.7 Input Value
  [6] pin6 ro — P6.6 Input Value
  [5] pin5 ro — P6.5 Input Value
  [4] pin4 ro — P6.4 Input Value
  [3] pin3 ro — P6.3 Input Value
  [2] pin2 ro — P6.2 Input Value
  [1] pin1 ro — P6.1 Input Value
  [0] pin0 ro — P6.0 Input Value
0x19C IN_VAL_P7 — Port P7 GPIO Input Value
  [7] pin7 ro — P7.7 Input Value
  [6] pin6 ro — P7.6 Input Value
  [5] pin5 ro — P7.5 Input Value
  [4] pin4 ro — P7.4 Input Value
  [3] pin3 ro — P7.3 Input Value
  [2] pin2 ro — P7.2 Input Value
  [1] pin1 ro — P7.1 Input Value
  [0] pin0 ro — P7.0 Input Value
0x1A0 IN_VAL_P8 — Port P8 GPIO Input Value
  [7] pin7 ro — P8.7 Input Value
  [6] pin6 ro — P8.6 Input Value
  [5] pin5 ro — P8.5 Input Value
  [4] pin4 ro — P8.4 Input Value
  [3] pin3 ro — P8.3 Input Value
  [2] pin2 ro — P8.2 Input Value
  [1] pin1 ro — P8.1 Input Value
  [0] pin0 ro — P8.0 Input Value
0x1C0 INT_MODE_P0 — Port P0 Interrupt Detection Mode
  [30:28] pin7 — P0.7 GPIO Interrupt Detection Mode
  [26:24] pin6 — P0.6 GPIO Interrupt Detection Mode
  [22:20] pin5 — P0.5 GPIO Interrupt Detection Mode
  [18:16] pin4 — P0.4 GPIO Interrupt Detection Mode
  [14:12] pin3 — P0.3 GPIO Interrupt Detection Mode
  [10:8] pin2 — P0.2 GPIO Interrupt Detection Mode
  [6:4] pin1 — P0.1 GPIO Interrupt Detection Mode
  [2:0] pin0 — P0.0 GPIO Interrupt Detection Mode
0x1C4 INT_MODE_P1 — Port P1 Interrupt Detection Mode
  [30:28] pin7 — P1.7 GPIO Interrupt Detection Mode
  [26:24] pin6 — P1.6 GPIO Interrupt Detection Mode
  [22:20] pin5 — P1.5 GPIO Interrupt Detection Mode
  [18:16] pin4 — P1.4 GPIO Interrupt Detection Mode
  [14:12] pin3 — P1.3 GPIO Interrupt Detection Mode
  [10:8] pin2 — P1.2 GPIO Interrupt Detection Mode
  [6:4] pin1 — P1.1 GPIO Interrupt Detection Mode
  [2:0] pin0 — P1.0 GPIO Interrupt Detection Mode
0x1C8 INT_MODE_P2 — Port P2 Interrupt Detection Mode
  [30:28] pin7 — P2.7 GPIO Interrupt Detection Mode
  [26:24] pin6 — P2.6 GPIO Interrupt Detection Mode
  [22:20] pin5 — P2.5 GPIO Interrupt Detection Mode
  [18:16] pin4 — P2.4 GPIO Interrupt Detection Mode
  [14:12] pin3 — P2.3 GPIO Interrupt Detection Mode
  [10:8] pin2 — P2.2 GPIO Interrupt Detection Mode
  [6:4] pin1 — P2.1 GPIO Interrupt Detection Mode
  [2:0] pin0 — P2.0 GPIO Interrupt Detection Mode
0x1CC INT_MODE_P3 — Port P3 Interrupt Detection Mode
  [30:28] pin7 — P3.7 GPIO Interrupt Detection Mode
  [26:24] pin6 — P3.6 GPIO Interrupt Detection Mode
  [22:20] pin5 — P3.5 GPIO Interrupt Detection Mode
  [18:16] pin4 — P3.4 GPIO Interrupt Detection Mode
  [14:12] pin3 — P3.3 GPIO Interrupt Detection Mode
  [10:8] pin2 — P3.2 GPIO Interrupt Detection Mode
  [6:4] pin1 — P3.1 GPIO Interrupt Detection Mode
  [2:0] pin0 — P3.0 GPIO Interrupt Detection Mode
0x1D0 INT_MODE_P4 — Port P4 Interrupt Detection Mode
  [30:28] pin7 — P4.7 GPIO Interrupt Detection Mode
  [26:24] pin6 — P4.6 GPIO Interrupt Detection Mode
  [22:20] pin5 — P4.5 GPIO Interrupt Detection Mode
  [18:16] pin4 — P4.4 GPIO Interrupt Detection Mode
  [14:12] pin3 — P4.3 GPIO Interrupt Detection Mode
  [10:8] pin2 — P4.2 GPIO Interrupt Detection Mode
  [6:4] pin1 — P4.1 GPIO Interrupt Detection Mode
  [2:0] pin0 — P4.0 GPIO Interrupt Detection Mode
0x1D4 INT_MODE_P5 — Port P5 Interrupt Detection Mode
  [30:28] pin7 — P5.7 GPIO Interrupt Detection Mode
  [26:24] pin6 — P5.6 GPIO Interrupt Detection Mode
  [22:20] pin5 — P5.5 GPIO Interrupt Detection Mode
  [18:16] pin4 — P5.4 GPIO Interrupt Detection Mode
  [14:12] pin3 — P5.3 GPIO Interrupt Detection Mode
  [10:8] pin2 — P5.2 GPIO Interrupt Detection Mode
  [6:4] pin1 — P5.1 GPIO Interrupt Detection Mode
  [2:0] pin0 — P5.0 GPIO Interrupt Detection Mode
0x1D8 INT_MODE_P6 — Port P6 Interrupt Detection Mode
  [30:28] pin7 — P6.7 GPIO Interrupt Detection Mode
  [26:24] pin6 — P6.6 GPIO Interrupt Detection Mode
  [22:20] pin5 — P6.5 GPIO Interrupt Detection Mode
  [18:16] pin4 — P6.4 GPIO Interrupt Detection Mode
  [14:12] pin3 — P6.3 GPIO Interrupt Detection Mode
  [10:8] pin2 — P6.2 GPIO Interrupt Detection Mode
  [6:4] pin1 — P6.1 GPIO Interrupt Detection Mode
  [2:0] pin0 — P6.0 GPIO Interrupt Detection Mode
0x1DC INT_MODE_P7 — Port P7 Interrupt Detection Mode
  [30:28] pin7 — P7.7 GPIO Interrupt Detection Mode
  [26:24] pin6 — P7.6 GPIO Interrupt Detection Mode
  [22:20] pin5 — P7.5 GPIO Interrupt Detection Mode
  [18:16] pin4 — P7.4 GPIO Interrupt Detection Mode
  [14:12] pin3 — P7.3 GPIO Interrupt Detection Mode
  [10:8] pin2 — P7.2 GPIO Interrupt Detection Mode
  [6:4] pin1 — P7.1 GPIO Interrupt Detection Mode
  [2:0] pin0 — P7.0 GPIO Interrupt Detection Mode
0x1E0 INT_MODE_P8 — Port P8 Interrupt Detection Mode
  [30:28] pin7 — P8.7 GPIO Interrupt Detection Mode
  [26:24] pin6 — P8.6 GPIO Interrupt Detection Mode
  [22:20] pin5 — P8.5 GPIO Interrupt Detection Mode
  [18:16] pin4 — P8.4 GPIO Interrupt Detection Mode
  [14:12] pin3 — P8.3 GPIO Interrupt Detection Mode
  [10:8] pin2 — P8.2 GPIO Interrupt Detection Mode
  [6:4] pin1 — P8.1 GPIO Interrupt Detection Mode
  [2:0] pin0 — P8.0 GPIO Interrupt Detection Mode
0x200 INTFL_P0 — Port P0 Interrupt Flags
  [7] pin7 write-1-clears — P0.7 External Interrupt Flags
  [6] pin6 write-1-clears — P0.6 External Interrupt Flags
  [5] pin5 write-1-clears — P0.5 External Interrupt Flags
  [4] pin4 write-1-clears — P0.4 External Interrupt Flags
  [3] pin3 write-1-clears — P0.3 External Interrupt Flags
  [2] pin2 write-1-clears — P0.2 External Interrupt Flags
  [1] pin1 write-1-clears — P0.1 External Interrupt Flags
  [0] pin0 write-1-clears — P0.0 External Interrupt Flags
0x204 INTFL_P1 — Port P1 Interrupt Flags
  [7] pin7 write-1-clears — P1.7 External Interrupt Flags
  [6] pin6 write-1-clears — P1.6 External Interrupt Flags
  [5] pin5 write-1-clears — P1.5 External Interrupt Flags
  [4] pin4 write-1-clears — P1.4 External Interrupt Flags
  [3] pin3 write-1-clears — P1.3 External Interrupt Flags
  [2] pin2 write-1-clears — P1.2 External Interrupt Flags
  [1] pin1 write-1-clears — P1.1 External Interrupt Flags
  [0] pin0 write-1-clears — P1.0 External Interrupt Flags
0x208 INTFL_P2 — Port P2 Interrupt Flags
  [7] pin7 write-1-clears — P2.7 External Interrupt Flags
  [6] pin6 write-1-clears — P2.6 External Interrupt Flags
  [5] pin5 write-1-clears — P2.5 External Interrupt Flags
  [4] pin4 write-1-clears — P2.4 External Interrupt Flags
  [3] pin3 write-1-clears — P2.3 External Interrupt Flags
  [2] pin2 write-1-clears — P2.2 External Interrupt Flags
  [1] pin1 write-1-clears — P2.1 External Interrupt Flags
  [0] pin0 write-1-clears — P2.0 External Interrupt Flags
0x20C INTFL_P3 — Port P3 Interrupt Flags
  [7] pin7 write-1-clears — P3.7 External Interrupt Flags
  [6] pin6 write-1-clears — P3.6 External Interrupt Flags
  [5] pin5 write-1-clears — P3.5 External Interrupt Flags
  [4] pin4 write-1-clears — P3.4 External Interrupt Flags
  [3] pin3 write-1-clears — P3.3 External Interrupt Flags
  [2] pin2 write-1-clears — P3.2 External Interrupt Flags
  [1] pin1 write-1-clears — P3.1 External Interrupt Flags
  [0] pin0 write-1-clears — P3.0 External Interrupt Flags
0x210 INTFL_P4 — Port P4 Interrupt Flags
  [7] pin7 write-1-clears — P4.7 External Interrupt Flags
  [6] pin6 write-1-clears — P4.6 External Interrupt Flags
  [5] pin5 write-1-clears — P4.5 External Interrupt Flags
  [4] pin4 write-1-clears — P4.4 External Interrupt Flags
  [3] pin3 write-1-clears — P4.3 External Interrupt Flags
  [2] pin2 write-1-clears — P4.2 External Interrupt Flags
  [1] pin1 write-1-clears — P4.1 External Interrupt Flags
  [0] pin0 write-1-clears — P4.0 External Interrupt Flags
0x214 INTFL_P5 — Port P5 Interrupt Flags
  [7] pin7 write-1-clears — P5.7 External Interrupt Flags
  [6] pin6 write-1-clears — P5.6 External Interrupt Flags
  [5] pin5 write-1-clears — P5.5 External Interrupt Flags
  [4] pin4 write-1-clears — P5.4 External Interrupt Flags
  [3] pin3 write-1-clears — P5.3 External Interrupt Flags
  [2] pin2 write-1-clears — P5.2 External Interrupt Flags
  [1] pin1 write-1-clears — P5.1 External Interrupt Flags
  [0] pin0 write-1-clears — P5.0 External Interrupt Flags
0x218 INTFL_P6 — Port P6 Interrupt Flags
  [7] pin7 write-1-clears — P6.7 External Interrupt Flags
  [6] pin6 write-1-clears — P6.6 External Interrupt Flags
  [5] pin5 write-1-clears — P6.5 External Interrupt Flags
  [4] pin4 write-1-clears — P6.4 External Interrupt Flags
  [3] pin3 write-1-clears — P6.3 External Interrupt Flags
  [2] pin2 write-1-clears — P6.2 External Interrupt Flags
  [1] pin1 write-1-clears — P6.1 External Interrupt Flags
  [0] pin0 write-1-clears — P6.0 External Interrupt Flags
0x21C INTFL_P7 — Port P7 Interrupt Flags
  [7] pin7 write-1-clears — P7.7 External Interrupt Flags
  [6] pin6 write-1-clears — P7.6 External Interrupt Flags
  [5] pin5 write-1-clears — P7.5 External Interrupt Flags
  [4] pin4 write-1-clears — P7.4 External Interrupt Flags
  [3] pin3 write-1-clears — P7.3 External Interrupt Flags
  [2] pin2 write-1-clears — P7.2 External Interrupt Flags
  [1] pin1 write-1-clears — P7.1 External Interrupt Flags
  [0] pin0 write-1-clears — P7.0 External Interrupt Flags
0x220 INTFL_P8 — Port P8 Interrupt Flags
  [7] pin7 write-1-clears — P8.7 External Interrupt Flags
  [6] pin6 write-1-clears — P8.6 External Interrupt Flags
  [5] pin5 write-1-clears — P8.5 External Interrupt Flags
  [4] pin4 write-1-clears — P8.4 External Interrupt Flags
  [3] pin3 write-1-clears — P8.3 External Interrupt Flags
  [2] pin2 write-1-clears — P8.2 External Interrupt Flags
  [1] pin1 write-1-clears — P8.1 External Interrupt Flags
  [0] pin0 write-1-clears — P8.0 External Interrupt Flags
0x240 INTEN_P0 — Port P0 Interrupt Enables
  [7] pin7 — P0.7 External Interrupt Enable
  [6] pin6 — P0.6 External Interrupt Enable
  [5] pin5 — P0.5 External Interrupt Enable
  [4] pin4 — P0.4 External Interrupt Enable
  [3] pin3 — P0.3 External Interrupt Enable
  [2] pin2 — P0.2 External Interrupt Enable
  [1] pin1 — P0.1 External Interrupt Enable
  [0] pin0 — P0.0 External Interrupt Enable
0x244 INTEN_P1 — Port P1 Interrupt Enables
  [7] pin7 — P1.7 External Interrupt Enable
  [6] pin6 — P1.6 External Interrupt Enable
  [5] pin5 — P1.5 External Interrupt Enable
  [4] pin4 — P1.4 External Interrupt Enable
  [3] pin3 — P1.3 External Interrupt Enable
  [2] pin2 — P1.2 External Interrupt Enable
  [1] pin1 — P1.1 External Interrupt Enable
  [0] pin0 — P1.0 External Interrupt Enable
0x248 INTEN_P2 — Port P2 Interrupt Enables
  [7] pin7 — P2.7 External Interrupt Enable
  [6] pin6 — P2.6 External Interrupt Enable
  [5] pin5 — P2.5 External Interrupt Enable
  [4] pin4 — P2.4 External Interrupt Enable
  [3] pin3 — P2.3 External Interrupt Enable
  [2] pin2 — P2.2 External Interrupt Enable
  [1] pin1 — P2.1 External Interrupt Enable
  [0] pin0 — P2.0 External Interrupt Enable
0x24C INTEN_P3 — Port P3 Interrupt Enables
  [7] pin7 — P3.7 External Interrupt Enable
  [6] pin6 — P3.6 External Interrupt Enable
  [5] pin5 — P3.5 External Interrupt Enable
  [4] pin4 — P3.4 External Interrupt Enable
  [3] pin3 — P3.3 External Interrupt Enable
  [2] pin2 — P3.2 External Interrupt Enable
  [1] pin1 — P3.1 External Interrupt Enable
  [0] pin0 — P3.0 External Interrupt Enable
0x250 INTEN_P4 — Port P4 Interrupt Enables
  [7] pin7 — P4.7 External Interrupt Enable
  [6] pin6 — P4.6 External Interrupt Enable
  [5] pin5 — P4.5 External Interrupt Enable
  [4] pin4 — P4.4 External Interrupt Enable
  [3] pin3 — P4.3 External Interrupt Enable
  [2] pin2 — P4.2 External Interrupt Enable
  [1] pin1 — P4.1 External Interrupt Enable
  [0] pin0 — P4.0 External Interrupt Enable
0x254 INTEN_P5 — Port P5 Interrupt Enables
  [7] pin7 — P5.7 External Interrupt Enable
  [6] pin6 — P5.6 External Interrupt Enable
  [5] pin5 — P5.5 External Interrupt Enable
  [4] pin4 — P5.4 External Interrupt Enable
  [3] pin3 — P5.3 External Interrupt Enable
  [2] pin2 — P5.2 External Interrupt Enable
  [1] pin1 — P5.1 External Interrupt Enable
  [0] pin0 — P5.0 External Interrupt Enable
0x258 INTEN_P6 — Port P6 Interrupt Enables
  [7] pin7 — P6.7 External Interrupt Enable
  [6] pin6 — P6.6 External Interrupt Enable
  [5] pin5 — P6.5 External Interrupt Enable
  [4] pin4 — P6.4 External Interrupt Enable
  [3] pin3 — P6.3 External Interrupt Enable
  [2] pin2 — P6.2 External Interrupt Enable
  [1] pin1 — P6.1 External Interrupt Enable
  [0] pin0 — P6.0 External Interrupt Enable
0x25C INTEN_P7 — Port P7 Interrupt Enables
  [7] pin7 — P7.7 External Interrupt Enable
  [6] pin6 — P7.6 External Interrupt Enable
  [5] pin5 — P7.5 External Interrupt Enable
  [4] pin4 — P7.4 External Interrupt Enable
  [3] pin3 — P7.3 External Interrupt Enable
  [2] pin2 — P7.2 External Interrupt Enable
  [1] pin1 — P7.1 External Interrupt Enable
  [0] pin0 — P7.0 External Interrupt Enable
0x260 INTEN_P8 — Port P8 Interrupt Enables
  [7] pin7 — P8.7 External Interrupt Enable
  [6] pin6 — P8.6 External Interrupt Enable
  [5] pin5 — P8.5 External Interrupt Enable
  [4] pin4 — P8.4 External Interrupt Enable
  [3] pin3 — P8.3 External Interrupt Enable
  [2] pin2 — P8.2 External Interrupt Enable
  [1] pin1 — P8.1 External Interrupt Enable
  [0] pin0 — P8.0 External Interrupt Enable
